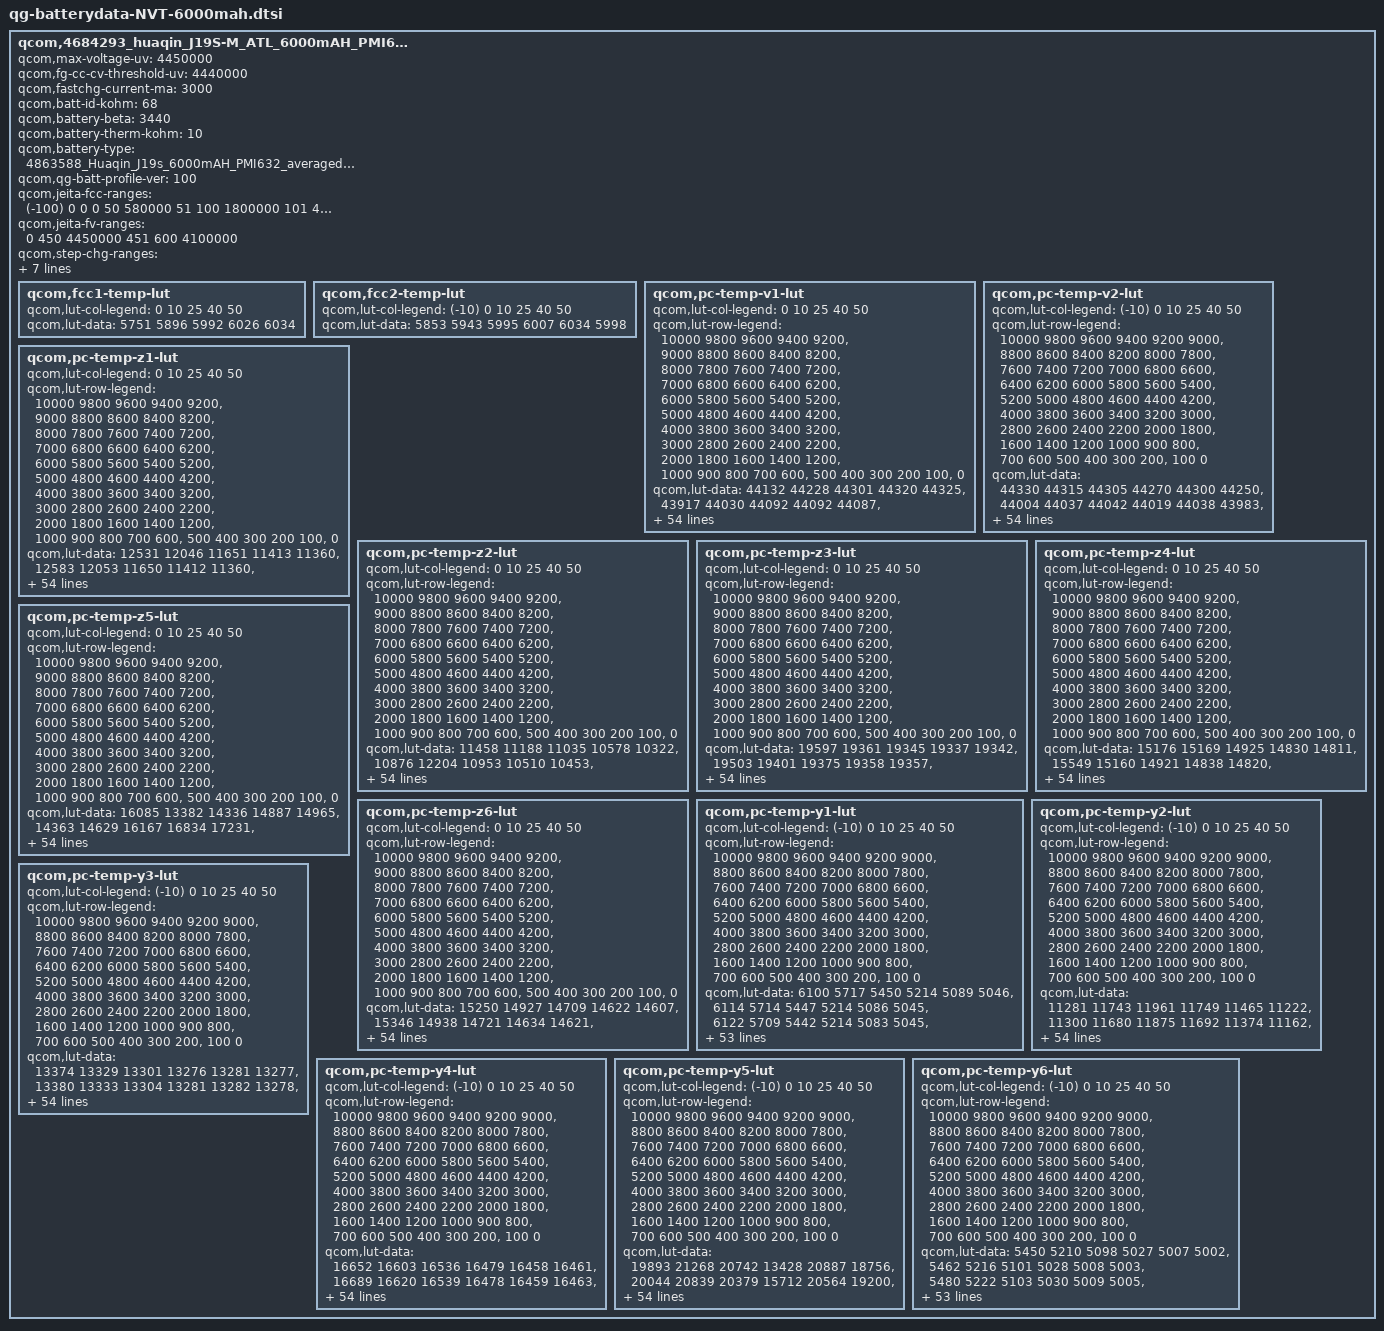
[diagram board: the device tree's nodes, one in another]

qcom,4684293_huaqin_J19S-M_ATL_6000mAH_PMI632 {
    /* 4684293_huaqin_J19S-M_ATL_6000mAH_PMI632_averaged_MasterSlave_Sep1th2020 */
    qcom,max-voltage-uv = <4450000>;
    qcom,fg-cc-cv-threshold-uv = <4440000>;
    qcom,fastchg-current-ma = <3000>;
    qcom,batt-id-kohm = <68>;
    qcom,battery-beta = <3440>;
    qcom,battery-therm-kohm = <10>;
    qcom,battery-type = "4863588_Huaqin_J19s_6000mAH_PMI632_averaged_MasterSlave_Oct22th2020";
    qcom,qg-batt-profile-ver = <100>;

	qcom,jeita-fcc-ranges = <(-100) 0 0
				0  50    580000
				51  100  1800000
				101 450  3000000
				451 600  3000000>;
	qcom,jeita-fv-ranges = <0   450   4450000
				451 600  4100000>;
	qcom,step-chg-ranges = <3600000  3800000  4500000
				3800001  4300000  3600000
				4300001  4350000  2500000>;
	qcom,ocv-based-step-chg;

	/* COOL = 5 DegC, WARM = 45 DegC */
	qcom,jeita-soft-thresholds = <0x439d 0x20b8>;
	/* COLD = 0 DegC, HOT = 60 DegC */
	qcom,jeita-hard-thresholds = <0x58cd 0x14f3>;
	/* COOL hys = 12 DegC, WARM hys = 40 DegC */
	qcom,jeita-soft-hys-thresholds = <0x4777 0x25e3>;
	qcom,jeita-soft-fcc-ua = <2500000 2500000>;
	qcom,jeita-soft-fv-uv = <4250000 4250000>;

	qcom,fcc1-temp-lut {
		qcom,lut-col-legend = <0 10 25 40 50>;
		qcom,lut-data = <5751 5896 5992 6026 6034>;
	};

	qcom,fcc2-temp-lut {
		qcom,lut-col-legend = <(-10) 0 10 25 40 50>;
		qcom,lut-data = <5853 5943 5995 6007 6034 5998>;
	};

	qcom,pc-temp-v1-lut {
		qcom,lut-col-legend = <0 10 25 40 50>;
		qcom,lut-row-legend = <10000 9800 9600 9400 9200>,
			<9000 8800 8600 8400 8200>,
			<8000 7800 7600 7400 7200>,
			<7000 6800 6600 6400 6200>,
			<6000 5800 5600 5400 5200>,
			<5000 4800 4600 4400 4200>,
			<4000 3800 3600 3400 3200>,
			<3000 2800 2600 2400 2200>,
			<2000 1800 1600 1400 1200>,
			<1000 900 800 700 600>,
			<500 400 300 200 100>,
			<0>;
		qcom,lut-data = <44132 44228 44301 44320 44325>,
			<43917 44030 44092 44092 44087>,
			<43700 43823 43881 43881 43874>,
			<43480 43606 43668 43670 43662>,
			<43255 43382 43455 43461 43451>,
			<43024 43153 43234 43247 43236>,
			<42792 42919 43001 43019 43010>,
			<42555 42682 42762 42781 42773>,
			<42319 42441 42524 42542 42535>,
			<42087 42201 42285 42301 42296>,
			<41858 41967 42048 42061 42058>,
			<41634 41736 41811 41824 41823>,
			<41416 41511 41576 41591 41589>,
			<41206 41291 41348 41362 41360>,
			<41001 41077 41126 41140 41137>,
			<40803 40873 40914 40924 40919>,
			<40611 40675 40712 40716 40710>,
			<40427 40486 40519 40515 40507>,
			<40249 40307 40339 40327 40318>,
			<40073 40131 40174 40159 40151>,
			<39908 39946 39991 39980 39976>,
			<39735 39753 39740 39738 39745>,
			<39517 39550 39470 39462 39475>,
			<39253 39309 39265 39254 39265>,
			<39043 39066 39102 39102 39112>,
			<38909 38913 38965 38970 38980>,
			<38804 38817 38854 38846 38852>,
			<38715 38735 38756 38733 38733>,
			<38640 38646 38659 38630 38626>,
			<38571 38560 38564 38537 38529>,
			<38505 38480 38478 38452 38442>,
			<38441 38405 38402 38371 38363>,
			<38384 38336 38333 38296 38290>,
			<38329 38275 38269 38228 38220>,
			<38279 38220 38211 38166 38153>,
			<38237 38170 38154 38105 38084>,
			<38203 38130 38100 38042 38015>,
			<38162 38087 38045 37977 37942>,
			<38104 38024 37973 37894 37853>,
			<38031 37937 37878 37785 37736>,
			<37942 37838 37772 37667 37610>,
			<37825 37721 37658 37554 37491>,
			<37688 37584 37527 37429 37364>,
			<37525 37417 37361 37262 37194>,
			<37365 37252 37209 37125 37060>,
			<37224 37137 37109 37040 36989>,
			<37179 37099 37075 37013 36962>,
			<37136 37075 37054 36989 36938>,
			<37100 37048 37028 36969 36912>,
			<37067 37004 36984 36902 36846>,
			<36994 36813 36761 36620 36573>,
			<36709 36362 36321 36166 36136>,
			<36203 35767 35742 35571 35560>,
			<35520 34933 34954 34754 34777>,
			<34375 33532 33743 33472 33556>,
			<30000 30000 30000 30000 30000>;
	};

	qcom,pc-temp-v2-lut {
		qcom,lut-col-legend = <(-10) 0 10 25 40 50>;
		qcom,lut-row-legend = <10000 9800 9600 9400 9200 9000>,
			<8800 8600 8400 8200 8000 7800>,
			<7600 7400 7200 7000 6800 6600>,
			<6400 6200 6000 5800 5600 5400>,
			<5200 5000 4800 4600 4400 4200>,
			<4000 3800 3600 3400 3200 3000>,
			<2800 2600 2400 2200 2000 1800>,
			<1600 1400 1200 1000 900 800>,
			<700 600 500 400 300 200>,
			<100 0>;
		qcom,lut-data = <44330 44315 44305 44270 44300 44250>,
			<44004 44037 44042 44019 44038 43983>,
			<43710 43775 43791 43780 43789 43731>,
			<43456 43534 43557 43553 43559 43498>,
			<43243 43314 43340 43340 43347 43285>,
			<43032 43093 43118 43122 43131 43069>,
			<42795 42854 42881 42888 42900 42837>,
			<42549 42609 42637 42646 42662 42599>,
			<42306 42365 42393 42406 42423 42362>,
			<42067 42122 42148 42166 42180 42121>,
			<41831 41882 41907 41928 41939 41883>,
			<41602 41645 41670 41691 41701 41646>,
			<41377 41413 41437 41456 41467 41414>,
			<41156 41189 41209 41227 41237 41186>,
			<40946 40974 40984 41002 41012 40963>,
			<40730 40764 40768 40785 40795 40749>,
			<40482 40563 40562 40577 40587 40543>,
			<40203 40364 40363 40376 40387 40345>,
			<39936 40145 40164 40186 40198 40160>,
			<39699 39892 39967 40008 40021 39987>,
			<39475 39639 39757 39811 39828 39801>,
			<39262 39407 39506 39548 39593 39564>,
			<39059 39187 39244 39269 39350 39310>,
			<38869 38993 39034 39058 39136 39101>,
			<38689 38820 38860 38888 38938 38920>,
			<38523 38664 38708 38742 38773 38765>,
			<38379 38526 38575 38614 38642 38634>,
			<38248 38402 38457 38501 38528 38521>,
			<38141 38284 38347 38396 38422 38416>,
			<38065 38169 38245 38299 38323 38317>,
			<38007 38066 38152 38210 38234 38228>,
			<37953 37985 38065 38127 38156 38151>,
			<37906 37916 37986 38051 38082 38078>,
			<37858 37860 37913 37979 38007 38001>,
			<37804 37819 37843 37913 37933 37921>,
			<37744 37781 37781 37841 37849 37832>,
			<37681 37739 37731 37752 37747 37720>,
			<37617 37697 37685 37657 37641 37599>,
			<37549 37645 37623 37566 37550 37497>,
			<37476 37580 37543 37477 37466 37411>,
			<37397 37497 37449 37380 37376 37322>,
			<37308 37378 37333 37271 37278 37222>,
			<37200 37213 37199 37149 37159 37109>,
			<37082 37043 37048 37005 37002 36962>,
			<36970 36883 36910 36898 36891 36849>,
			<36865 36767 36813 36859 36846 36804>,
			<36817 36732 36786 36839 36836 36791>,
			<36774 36692 36736 36821 36819 36774>,
			<36733 36652 36678 36770 36787 36744>,
			<36683 36598 36562 36601 36675 36648>,
			<36620 36490 36275 36157 36343 36303>,
			<36516 36169 35758 35565 35812 35797>,
			<36313 35571 35059 34761 35119 35131>,
			<35859 34672 34014 33536 34124 34192>,
			<34932 33339 32289 31776 32784 32738>,
			<33834 31683 28227 29230 27680 30138>;
	};

	qcom,pc-temp-z1-lut {
		qcom,lut-col-legend = <0 10 25 40 50>;
		qcom,lut-row-legend = <10000 9800 9600 9400 9200>,
			<9000 8800 8600 8400 8200>,
			<8000 7800 7600 7400 7200>,
			<7000 6800 6600 6400 6200>,
			<6000 5800 5600 5400 5200>,
			<5000 4800 4600 4400 4200>,
			<4000 3800 3600 3400 3200>,
			<3000 2800 2600 2400 2200>,
			<2000 1800 1600 1400 1200>,
			<1000 900 800 700 600>,
			<500 400 300 200 100>,
			<0>;
		qcom,lut-data = <12531 12046 11651 11413 11360>,
			<12583 12053 11650 11412 11360>,
			<12569 12053 11649 11410 11358>,
			<12553 12048 11647 11409 11357>,
			<12540 12039 11644 11407 11355>,
			<12526 12029 11640 11405 11354>,
			<12514 12018 11636 11404 11355>,
			<12500 12006 11631 11402 11355>,
			<12488 11993 11627 11402 11356>,
			<12478 11980 11622 11402 11359>,
			<12466 11970 11620 11402 11362>,
			<12458 11962 11620 11403 11365>,
			<12453 11956 11621 11405 11369>,
			<12444 11951 11620 11406 11370>,
			<12432 11948 11619 11405 11371>,
			<12415 11948 11619 11405 11371>,
			<12401 11950 11619 11404 11371>,
			<12394 11951 11619 11404 11371>,
			<12389 11951 11620 11404 11371>,
			<12386 11950 11622 11405 11372>,
			<12382 11950 11623 11405 11373>,
			<12379 11950 11624 11405 11373>,
			<12381 11950 11624 11404 11373>,
			<12387 11951 11625 11404 11374>,
			<12389 11952 11627 11404 11375>,
			<12391 11954 11629 11406 11377>,
			<12394 11960 11632 11408 11378>,
			<12395 11966 11635 11411 11380>,
			<12392 11967 11637 11413 11381>,
			<12390 11967 11639 11415 11383>,
			<12392 11969 11641 11417 11386>,
			<12396 11975 11644 11419 11388>,
			<12400 11982 11648 11420 11390>,
			<12409 11988 11652 11423 11392>,
			<12419 11994 11655 11426 11395>,
			<12424 11999 11660 11429 11397>,
			<12428 12006 11666 11432 11400>,
			<12435 12012 11673 11435 11402>,
			<12447 12015 11678 11438 11405>,
			<12462 12018 11682 11440 11407>,
			<12472 12021 11686 11443 11408>,
			<12482 12032 11691 11445 11411>,
			<12492 12042 11696 11447 11413>,
			<12514 12051 11702 11450 11415>,
			<12549 12062 11713 11454 11418>,
			<12527 12085 11721 11456 11419>,
			<12534 12072 11723 11456 11419>,
			<12535 12082 11723 11456 11420>,
			<12541 12091 11721 11458 11422>,
			<12534 12090 11732 11460 11425>,
			<12549 12102 11742 11465 11428>,
			<12562 12114 11753 11471 11435>,
			<12575 12129 11768 11480 11443>,
			<12590 12141 11781 11492 11456>,
			<12590 12141 11781 11492 11456>,
			<12590 12141 11781 11492 11456>;
	};

	qcom,pc-temp-z2-lut {
		qcom,lut-col-legend = <0 10 25 40 50>;
		qcom,lut-row-legend = <10000 9800 9600 9400 9200>,
			<9000 8800 8600 8400 8200>,
			<8000 7800 7600 7400 7200>,
			<7000 6800 6600 6400 6200>,
			<6000 5800 5600 5400 5200>,
			<5000 4800 4600 4400 4200>,
			<4000 3800 3600 3400 3200>,
			<3000 2800 2600 2400 2200>,
			<2000 1800 1600 1400 1200>,
			<1000 900 800 700 600>,
			<500 400 300 200 100>,
			<0>;
		qcom,lut-data = <11458 11188 11035 10578 10322>,
			<10876 12204 10953 10510 10453>,
			<10821 12374 10888 10578 10448>,
			<10796 11660 10845 10602 10448>,
			<10770 10976 10814 10574 10491>,
			<10747 10894 10787 10543 10541>,
			<10727 10856 10749 10533 10534>,
			<10707 10830 10707 10524 10495>,
			<10693 10811 10724 10512 10466>,
			<10691 10799 10952 10476 10444>,
			<10691 10798 11122 10447 10427>,
			<10694 10798 10964 10450 10424>,
			<10707 10798 10689 10459 10426>,
			<10728 10809 10630 10466 10428>,
			<10751 10831 10653 10478 10435>,
			<10776 10900 10689 10493 10445>,
			<10804 11102 10870 10516 10458>,
			<10839 11226 11161 10546 10483>,
			<10879 11139 11360 10557 10488>,
			<10918 11003 11725 10551 10413>,
			<10957 10982 11923 10546 10339>,
			<10992 10993 11627 10656 10454>,
			<11021 11000 11144 10883 10751>,
			<11048 11002 10954 10935 10844>,
			<11059 11003 10864 10799 10689>,
			<11046 11005 10828 10686 10544>,
			<11027 11013 10856 10753 10633>,
			<11023 11021 10897 10892 10855>,
			<11026 11027 10907 10916 10915>,
			<11031 11032 10901 10793 10743>,
			<11038 11034 10890 10666 10550>,
			<11049 11034 10866 10604 10461>,
			<11057 11034 10838 10559 10398>,
			<11064 11042 10832 10550 10349>,
			<11072 11061 10834 10553 10301>,
			<11080 11080 10839 10559 10275>,
			<11090 11098 10874 10595 10304>,
			<11104 11117 10937 10673 10387>,
			<11128 11146 10991 10756 10494>,
			<11157 11182 11047 10870 10676>,
			<11175 11199 11078 10937 10802>,
			<11184 11201 11086 10915 10809>,
			<11199 11204 11089 10884 10807>,
			<11235 11221 11068 10879 10835>,
			<11568 11402 11106 10886 10830>,
			<11545 11518 11122 10833 10648>,
			<11370 11511 11141 10737 10554>,
			<11282 11707 11100 10721 10585>,
			<11202 12151 11124 10808 10609>,
			<11119 12342 11183 10882 10694>,
			<11069 12198 11169 10757 10626>,
			<10955 11889 11064 10504 10324>,
			<10660 11647 10959 10410 10244>,
			<10499 11104 10884 10323 10174>,
			<10499 11104 10884 10323 10174>,
			<10499 11104 10884 10323 10174>;
	};

	qcom,pc-temp-z3-lut {
		qcom,lut-col-legend = <0 10 25 40 50>;
		qcom,lut-row-legend = <10000 9800 9600 9400 9200>,
			<9000 8800 8600 8400 8200>,
			<8000 7800 7600 7400 7200>,
			<7000 6800 6600 6400 6200>,
			<6000 5800 5600 5400 5200>,
			<5000 4800 4600 4400 4200>,
			<4000 3800 3600 3400 3200>,
			<3000 2800 2600 2400 2200>,
			<2000 1800 1600 1400 1200>,
			<1000 900 800 700 600>,
			<500 400 300 200 100>,
			<0>;
		qcom,lut-data = <19597 19361 19345 19337 19342>,
			<19503 19401 19375 19358 19357>,
			<19567 19422 19400 19378 19371>,
			<19613 19461 19417 19389 19382>,
			<19625 19497 19430 19394 19389>,
			<19633 19505 19438 19399 19396>,
			<19635 19510 19443 19403 19401>,
			<19635 19511 19446 19408 19405>,
			<19634 19511 19448 19409 19406>,
			<19633 19510 19456 19410 19406>,
			<19632 19508 19460 19411 19405>,
			<19630 19503 19453 19409 19403>,
			<19624 19498 19441 19405 19400>,
			<19615 19492 19433 19402 19397>,
			<19609 19487 19428 19398 19394>,
			<19604 19487 19425 19394 19391>,
			<19599 19495 19425 19392 19388>,
			<19592 19499 19428 19389 19384>,
			<19584 19486 19429 19385 19379>,
			<19580 19468 19430 19378 19371>,
			<19577 19467 19431 19372 19366>,
			<19575 19477 19431 19378 19368>,
			<19583 19486 19432 19391 19375>,
			<19608 19490 19429 19393 19376>,
			<19621 19492 19411 19376 19366>,
			<19614 19490 19399 19362 19356>,
			<19602 19478 19399 19377 19371>,
			<19593 19468 19399 19408 19407>,
			<19586 19469 19401 19416 19419>,
			<19580 19472 19413 19412 19414>,
			<19578 19475 19421 19408 19407>,
			<19577 19477 19420 19404 19400>,
			<19576 19478 19416 19398 19392>,
			<19574 19478 19413 19392 19384>,
			<19573 19476 19408 19382 19373>,
			<19571 19474 19404 19373 19364>,
			<19568 19470 19399 19366 19357>,
			<19565 19467 19395 19360 19352>,
			<19560 19463 19393 19360 19350>,
			<19553 19459 19392 19364 19351>,
			<19546 19454 19392 19367 19352>,
			<19537 19449 19387 19365 19355>,
			<19525 19442 19382 19364 19362>,
			<19507 19434 19379 19367 19367>,
			<19388 19411 19372 19363 19366>,
			<19346 19394 19362 19352 19353>,
			<19297 19391 19362 19340 19344>,
			<19291 19357 19356 19338 19330>,
			<19288 19293 19355 19327 19326>,
			<19286 19286 19343 19325 19320>,
			<19284 19290 19354 19343 19332>,
			<19289 19297 19364 19357 19350>,
			<19294 19296 19367 19357 19350>,
			<19306 19324 19370 19358 19352>,
			<19306 19324 19370 19358 19352>,
			<19306 19324 19370 19358 19352>;
	};

	qcom,pc-temp-z4-lut {
		qcom,lut-col-legend = <0 10 25 40 50>;
		qcom,lut-row-legend = <10000 9800 9600 9400 9200>,
			<9000 8800 8600 8400 8200>,
			<8000 7800 7600 7400 7200>,
			<7000 6800 6600 6400 6200>,
			<6000 5800 5600 5400 5200>,
			<5000 4800 4600 4400 4200>,
			<4000 3800 3600 3400 3200>,
			<3000 2800 2600 2400 2200>,
			<2000 1800 1600 1400 1200>,
			<1000 900 800 700 600>,
			<500 400 300 200 100>,
			<0>;
		qcom,lut-data = <15176 15169 14925 14830 14811>,
			<15549 15160 14921 14838 14820>,
			<15462 15140 14909 14830 14818>,
			<15358 15079 14890 14820 14814>,
			<15270 15007 14855 14804 14801>,
			<15184 14958 14821 14785 14782>,
			<15115 14917 14797 14769 14768>,
			<15061 14882 14776 14755 14755>,
			<15015 14853 14753 14741 14743>,
			<14975 14829 14721 14729 14731>,
			<14941 14810 14700 14717 14720>,
			<14913 14795 14698 14706 14710>,
			<14891 14782 14701 14697 14701>,
			<14873 14771 14699 14691 14695>,
			<14856 14761 14695 14688 14692>,
			<14841 14745 14690 14686 14690>,
			<14827 14721 14679 14683 14688>,
			<14816 14709 14666 14679 14687>,
			<14806 14719 14657 14676 14684>,
			<14795 14733 14643 14673 14679>,
			<14781 14736 14635 14670 14675>,
			<14770 14736 14667 14687 14691>,
			<14777 14736 14724 14728 14735>,
			<14806 14764 14760 14756 14761>,
			<14828 14811 14787 14776 14774>,
			<14838 14822 14799 14787 14781>,
			<14844 14817 14792 14766 14760>,
			<14844 14809 14776 14721 14709>,
			<14836 14798 14760 14701 14689>,
			<14825 14781 14739 14694 14686>,
			<14815 14768 14723 14690 14684>,
			<14805 14756 14715 14685 14681>,
			<14797 14748 14708 14682 14678>,
			<14791 14744 14705 14680 14675>,
			<14785 14741 14702 14679 14673>,
			<14781 14739 14700 14678 14672>,
			<14777 14738 14699 14677 14671>,
			<14772 14737 14699 14677 14670>,
			<14765 14735 14700 14678 14671>,
			<14755 14733 14703 14685 14684>,
			<14743 14730 14706 14690 14694>,
			<14727 14718 14703 14687 14687>,
			<14709 14703 14696 14683 14677>,
			<14687 14687 14690 14683 14681>,
			<14734 14661 14670 14671 14672>,
			<14763 14650 14655 14657 14654>,
			<14815 14646 14649 14660 14655>,
			<14817 14673 14641 14652 14655>,
			<14816 14740 14629 14644 14640>,
			<14815 14744 14631 14632 14631>,
			<14812 14742 14634 14652 14662>,
			<14812 14746 14638 14656 14670>,
			<14820 14753 14639 14660 14676>,
			<14826 14737 14640 14662 14677>,
			<14826 14737 14640 14662 14677>,
			<14826 14737 14640 14662 14677>;
	};

	qcom,pc-temp-z5-lut {
		qcom,lut-col-legend = <0 10 25 40 50>;
		qcom,lut-row-legend = <10000 9800 9600 9400 9200>,
			<9000 8800 8600 8400 8200>,
			<8000 7800 7600 7400 7200>,
			<7000 6800 6600 6400 6200>,
			<6000 5800 5600 5400 5200>,
			<5000 4800 4600 4400 4200>,
			<4000 3800 3600 3400 3200>,
			<3000 2800 2600 2400 2200>,
			<2000 1800 1600 1400 1200>,
			<1000 900 800 700 600>,
			<500 400 300 200 100>,
			<0>;
		qcom,lut-data = <16085 13382 14336 14887 14965>,
			<14363 14629 16167 16834 17231>,
			<15574 15379 17778 19023 19384>,
			<16599 16680 19126 20403 21219>,
			<17072 18009 20283 21084 22685>,
			<17417 18593 21314 21694 24031>,
			<17813 18997 22238 22598 25497>,
			<18271 19459 23068 23700 27016>,
			<18785 20082 24265 24772 28303>,
			<19430 20710 27382 25797 29283>,
			<20267 21184 29637 26824 30238>,
			<21038 21575 29042 27905 31496>,
			<21615 21990 27714 29001 33015>,
			<22160 22396 27795 29908 34339>,
			<22837 22907 28581 30579 35392>,
			<23707 24507 29636 31292 36398>,
			<24579 28593 32112 32560 37668>,
			<25266 30869 35756 34080 39050>,
			<25919 28912 38469 34377 39403>,
			<26911 26036 42030 33082 38040>,
			<28655 26471 45052 31959 36710>,
			<31451 31753 47979 35700 38048>,
			<38622 35530 50690 43708 41561>,
			<53252 35779 48426 44569 41948>,
			<60874 35897 34173 31280 30928>,
			<55148 35205 24032 20241 20656>,
			<45655 30177 22648 22806 24463>,
			<40774 26187 21899 28684 34385>,
			<37861 26454 22390 31136 38127>,
			<36404 27459 25657 31844 38565>,
			<36582 28815 28674 32410 38651>,
			<37235 31250 30135 33258 38005>,
			<38078 33866 31283 34121 36474>,
			<39526 35948 32357 34103 34759>,
			<41140 37810 33429 32472 32332>,
			<42182 38542 34110 30973 30690>,
			<42994 38679 34369 30465 30561>,
			<44008 38803 34578 30140 30508>,
			<46290 39262 34930 30645 30672>,
			<48875 40148 35671 34373 32157>,
			<49532 40530 36102 37060 33577>,
			<49390 40504 34001 33661 33892>,
			<48809 40459 31849 29690 34253>,
			<45570 40449 32631 32969 39691>,
			<26530 42287 35947 35064 42501>,
			<19522 36526 34159 29876 33097>,
			<13487 35644 35350 23126 24914>,
			<13205 20804 33269 24004 19965>,
			<13056 13671 37766 23009 22486>,
			<12916 13319 28315 26507 25152>,
			<12873 13556 33573 29441 26413>,
			<13075 13709 30640 25825 22503>,
			<12990 13496 29247 22851 19646>,
			<13504 15092 27619 20363 17642>,
			<13504 15092 27619 20363 17642>,
			<13504 15092 27619 20363 17642>;
	};

	qcom,pc-temp-z6-lut {
		qcom,lut-col-legend = <0 10 25 40 50>;
		qcom,lut-row-legend = <10000 9800 9600 9400 9200>,
			<9000 8800 8600 8400 8200>,
			<8000 7800 7600 7400 7200>,
			<7000 6800 6600 6400 6200>,
			<6000 5800 5600 5400 5200>,
			<5000 4800 4600 4400 4200>,
			<4000 3800 3600 3400 3200>,
			<3000 2800 2600 2400 2200>,
			<2000 1800 1600 1400 1200>,
			<1000 900 800 700 600>,
			<500 400 300 200 100>,
			<0>;
		qcom,lut-data = <15250 14927 14709 14622 14607>,
			<15346 14938 14721 14634 14621>,
			<15325 14939 14727 14641 14627>,
			<15296 14926 14726 14643 14629>,
			<15261 14908 14717 14639 14627>,
			<15217 14892 14707 14633 14624>,
			<15180 14872 14699 14629 14622>,
			<15149 14853 14690 14625 14619>,
			<15122 14837 14682 14621 14615>,
			<15098 14823 14673 14616 14611>,
			<15078 14811 14665 14612 14607>,
			<15059 14799 14659 14606 14602>,
			<15041 14789 14654 14600 14597>,
			<15024 14779 14649 14596 14593>,
			<15009 14771 14645 14592 14590>,
			<14996 14764 14640 14589 14587>,
			<14985 14759 14637 14586 14584>,
			<14973 14754 14633 14583 14581>,
			<14963 14751 14629 14579 14577>,
			<14954 14748 14624 14573 14570>,
			<14947 14748 14622 14569 14565>,
			<14942 14752 14637 14581 14574>,
			<14949 14759 14662 14607 14597>,
			<14976 14775 14671 14615 14606>,
			<14991 14796 14674 14615 14606>,
			<14991 14800 14675 14615 14606>,
			<14989 14793 14672 14614 14605>,
			<14986 14785 14666 14611 14603>,
			<14980 14780 14662 14608 14601>,
			<14973 14776 14659 14604 14598>,
			<14969 14772 14657 14599 14594>,
			<14965 14769 14653 14595 14589>,
			<14962 14767 14649 14591 14584>,
			<14959 14766 14646 14587 14578>,
			<14957 14765 14643 14582 14573>,
			<14956 14764 14640 14577 14567>,
			<14956 14763 14638 14573 14563>,
			<14955 14762 14636 14570 14559>,
			<14954 14762 14637 14570 14559>,
			<14952 14761 14639 14575 14564>,
			<14949 14759 14640 14579 14569>,
			<14944 14755 14638 14577 14568>,
			<14939 14749 14633 14575 14567>,
			<14931 14741 14630 14576 14571>,
			<14903 14725 14620 14570 14568>,
			<14897 14714 14610 14558 14553>,
			<14895 14711 14607 14553 14549>,
			<14894 14707 14602 14549 14543>,
			<14895 14706 14596 14539 14534>,
			<14896 14707 14592 14534 14526>,
			<14899 14713 14602 14552 14546>,
			<14909 14723 14611 14564 14562>,
			<14922 14732 14616 14568 14568>,
			<14944 14748 14623 14572 14573>,
			<14944 14748 14623 14572 14573>,
			<14944 14748 14623 14572 14573>;
	};

	qcom,pc-temp-y1-lut {
		qcom,lut-col-legend = <(-10) 0 10 25 40 50>;
		qcom,lut-row-legend = <10000 9800 9600 9400 9200 9000>,
			<8800 8600 8400 8200 8000 7800>,
			<7600 7400 7200 7000 6800 6600>,
			<6400 6200 6000 5800 5600 5400>,
			<5200 5000 4800 4600 4400 4200>,
			<4000 3800 3600 3400 3200 3000>,
			<2800 2600 2400 2200 2000 1800>,
			<1600 1400 1200 1000 900 800>,
			<700 600 500 400 300 200>,
			<100 0>;
		qcom,lut-data = <6100 5717 5450 5214 5089 5046>,
			<6114 5714 5447 5214 5086 5045>,
			<6122 5709 5442 5214 5083 5045>,
			<6126 5702 5437 5213 5080 5044>,
			<6126 5697 5432 5213 5077 5043>,
			<6124 5694 5430 5212 5075 5043>,
			<6117 5694 5428 5209 5072 5043>,
			<6107 5694 5427 5207 5070 5043>,
			<6101 5693 5426 5206 5069 5042>,
			<6103 5688 5424 5205 5068 5042>,
			<6107 5684 5422 5205 5067 5042>,
			<6110 5687 5419 5204 5067 5042>,
			<6115 5693 5415 5203 5066 5043>,
			<6117 5694 5413 5203 5066 5043>,
			<6112 5694 5411 5203 5065 5043>,
			<6105 5693 5410 5203 5065 5043>,
			<6109 5692 5412 5203 5065 5043>,
			<6122 5690 5416 5203 5066 5044>,
			<6127 5690 5416 5203 5066 5044>,
			<6119 5692 5415 5205 5065 5045>,
			<6109 5694 5413 5207 5065 5045>,
			<6107 5693 5413 5207 5065 5045>,
			<6116 5691 5413 5206 5067 5045>,
			<6125 5691 5414 5207 5068 5046>,
			<6133 5699 5418 5209 5069 5046>,
			<6143 5707 5422 5211 5070 5046>,
			<6144 5708 5424 5212 5071 5047>,
			<6131 5706 5426 5212 5072 5048>,
			<6118 5705 5428 5213 5073 5049>,
			<6115 5707 5432 5216 5075 5051>,
			<6113 5710 5435 5219 5077 5053>,
			<6110 5710 5435 5222 5078 5053>,
			<6099 5709 5435 5225 5079 5054>,
			<6087 5708 5435 5226 5080 5055>,
			<6084 5709 5438 5226 5082 5056>,
			<6087 5710 5440 5227 5083 5057>,
			<6090 5708 5443 5228 5084 5058>,
			<6094 5705 5447 5231 5085 5058>,
			<6102 5706 5449 5233 5085 5059>,
			<6110 5716 5451 5235 5086 5061>,
			<6117 5726 5452 5236 5086 5062>,
			<6120 5726 5454 5237 5088 5063>,
			<6108 5722 5458 5238 5089 5063>,
			<6097 5719 5464 5240 5090 5063>,
			<6103 5717 5472 5246 5093 5065>,
			<6116 5726 5475 5250 5093 5066>,
			<6133 5738 5485 5250 5094 5066>,
			<6128 5733 5487 5250 5093 5067>,
			<6136 5737 5492 5246 5093 5066>,
			<6173 5752 5496 5249 5094 5067>,
			<6191 5767 5505 5257 5096 5069>,
			<6254 5805 5506 5265 5100 5072>,
			<6307 5855 5554 5275 5106 5079>,
			<6288 5927 5615 5302 5115 5085>,
			<6288 5927 5615 5302 5115 5085>,
			<6288 5927 5615 5302 5115 5085>;
	};

	qcom,pc-temp-y2-lut {
		qcom,lut-col-legend = <(-10) 0 10 25 40 50>;
		qcom,lut-row-legend = <10000 9800 9600 9400 9200 9000>,
			<8800 8600 8400 8200 8000 7800>,
			<7600 7400 7200 7000 6800 6600>,
			<6400 6200 6000 5800 5600 5400>,
			<5200 5000 4800 4600 4400 4200>,
			<4000 3800 3600 3400 3200 3000>,
			<2800 2600 2400 2200 2000 1800>,
			<1600 1400 1200 1000 900 800>,
			<700 600 500 400 300 200>,
			<100 0>;
		qcom,lut-data = <11281 11743 11961 11749 11465 11222>,
			<11300 11680 11875 11692 11374 11162>,
			<11309 11619 11794 11625 11287 11090>,
			<11309 11562 11718 11555 11206 11018>,
			<11304 11510 11651 11490 11135 10958>,
			<11296 11462 11593 11439 11076 10919>,
			<11275 11416 11545 11394 11022 10895>,
			<11247 11376 11504 11353 10980 10878>,
			<11239 11355 11465 11324 10970 10877>,
			<11246 11341 11423 11297 10977 10888>,
			<11259 11335 11404 11284 10981 10895>,
			<11283 11350 11407 11288 10965 10870>,
			<11322 11387 11414 11295 10943 10831>,
			<11358 11424 11428 11297 10943 10821>,
			<11392 11462 11459 11298 10956 10834>,
			<11417 11505 11500 11299 10971 10840>,
			<11419 11568 11549 11317 10991 10822>,
			<11418 11638 11607 11354 11021 10798>,
			<11417 11656 11670 11415 11059 10807>,
			<11415 11648 11746 11529 11112 10891>,
			<11412 11640 11786 11596 11174 10980>,
			<11411 11634 11770 11594 11269 11044>,
			<11411 11627 11744 11588 11353 11100>,
			<11412 11629 11744 11598 11363 11135>,
			<11414 11642 11771 11637 11356 11168>,
			<11419 11658 11798 11672 11352 11187>,
			<11430 11672 11817 11691 11357 11197>,
			<11462 11689 11833 11706 11369 11212>,
			<11489 11710 11841 11718 11401 11242>,
			<11490 11740 11844 11737 11469 11328>,
			<11479 11772 11844 11758 11526 11416>,
			<11443 11804 11850 11794 11566 11481>,
			<11053 11846 11861 11832 11591 11540>,
			<10575 11861 11870 11834 11622 11599>,
			<10285 11793 11884 11809 11712 11666>,
			<9882 11676 11891 11788 11742 11699>,
			<9705 11558 11862 11755 11686 11645>,
			<9689 11416 11801 11722 11621 11555>,
			<9681 11268 11745 11721 11589 11523>,
			<9675 11138 11689 11729 11565 11516>,
			<9672 10978 11617 11727 11559 11510>,
			<9669 10615 11492 11707 11578 11455>,
			<9667 10008 11335 11682 11578 11375>,
			<9664 9785 11197 11659 11457 11276>,
			<9662 9706 10993 11597 11322 11127>,
			<9659 9677 10867 11517 11193 11013>,
			<9657 9671 10753 11473 11178 11004>,
			<9656 9665 10398 11497 11193 11020>,
			<9654 9661 10052 11487 11234 11085>,
			<9651 9656 9837 11504 11226 11090>,
			<9650 9653 9692 11406 11121 10942>,
			<9649 9650 9662 11316 11005 10881>,
			<9648 9649 9654 11168 10892 10729>,
			<9648 9649 9654 11029 10655 10568>,
			<9648 9649 9654 11029 10655 10568>,
			<9648 9649 9654 11029 10655 10568>;
	};

	qcom,pc-temp-y3-lut {
		qcom,lut-col-legend = <(-10) 0 10 25 40 50>;
		qcom,lut-row-legend = <10000 9800 9600 9400 9200 9000>,
			<8800 8600 8400 8200 8000 7800>,
			<7600 7400 7200 7000 6800 6600>,
			<6400 6200 6000 5800 5600 5400>,
			<5200 5000 4800 4600 4400 4200>,
			<4000 3800 3600 3400 3200 3000>,
			<2800 2600 2400 2200 2000 1800>,
			<1600 1400 1200 1000 900 800>,
			<700 600 500 400 300 200>,
			<100 0>;
		qcom,lut-data = <13374 13329 13301 13276 13281 13277>,
			<13380 13333 13304 13281 13282 13278>,
			<13389 13337 13307 13285 13282 13279>,
			<13399 13341 13309 13288 13283 13280>,
			<13407 13344 13311 13289 13283 13281>,
			<13412 13346 13312 13290 13284 13281>,
			<13413 13348 13312 13289 13284 13282>,
			<13413 13350 13312 13287 13284 13282>,
			<13414 13352 13312 13287 13284 13283>,
			<13413 13354 13313 13292 13286 13283>,
			<13413 13355 13314 13296 13286 13284>,
			<13413 13354 13315 13296 13287 13284>,
			<13414 13352 13317 13297 13287 13285>,
			<13414 13350 13317 13297 13287 13285>,
			<13411 13349 13317 13296 13287 13285>,
			<13404 13349 13316 13296 13287 13285>,
			<13399 13349 13316 13296 13289 13286>,
			<13393 13351 13317 13298 13292 13288>,
			<13388 13351 13317 13299 13293 13289>,
			<13383 13346 13319 13300 13294 13291>,
			<13378 13339 13320 13301 13294 13292>,
			<13374 13335 13316 13298 13292 13289>,
			<13371 13331 13310 13292 13288 13284>,
			<13368 13328 13306 13290 13286 13282>,
			<13363 13326 13303 13288 13283 13280>,
			<13357 13324 13302 13287 13281 13280>,
			<13349 13323 13301 13286 13281 13280>,
			<13333 13323 13301 13285 13280 13280>,
			<13322 13322 13301 13285 13279 13280>,
			<13319 13317 13300 13285 13278 13279>,
			<13317 13312 13300 13285 13278 13278>,
			<13318 13309 13300 13285 13278 13278>,
			<13324 13306 13299 13285 13278 13279>,
			<13335 13305 13299 13286 13279 13280>,
			<13350 13308 13297 13286 13280 13281>,
			<13373 13313 13296 13286 13280 13281>,
			<13400 13318 13297 13285 13279 13280>,
			<13433 13324 13299 13285 13278 13279>,
			<13472 13330 13300 13285 13279 13279>,
			<13519 13339 13301 13285 13280 13280>,
			<13577 13346 13302 13286 13281 13281>,
			<13647 13349 13304 13286 13282 13280>,
			<13731 13350 13306 13286 13282 13280>,
			<13842 13364 13310 13284 13279 13278>,
			<14012 13409 13316 13284 13280 13278>,
			<14273 13487 13316 13290 13284 13283>,
			<14457 13539 13323 13291 13287 13285>,
			<14662 13656 13327 13295 13289 13288>,
			<15044 13882 13344 13296 13290 13289>,
			<15993 14303 13382 13296 13288 13287>,
			<18027 15250 13482 13292 13284 13283>,
			<22373 17989 13795 13296 13285 13283>,
			<33012 26447 15207 13304 13288 13287>,
			<65535 65085 20503 13323 13295 13295>,
			<65535 65085 20503 13323 13295 13295>,
			<65535 65085 20503 13323 13295 13295>;
	};

	qcom,pc-temp-y4-lut {
		qcom,lut-col-legend = <(-10) 0 10 25 40 50>;
		qcom,lut-row-legend = <10000 9800 9600 9400 9200 9000>,
			<8800 8600 8400 8200 8000 7800>,
			<7600 7400 7200 7000 6800 6600>,
			<6400 6200 6000 5800 5600 5400>,
			<5200 5000 4800 4600 4400 4200>,
			<4000 3800 3600 3400 3200 3000>,
			<2800 2600 2400 2200 2000 1800>,
			<1600 1400 1200 1000 900 800>,
			<700 600 500 400 300 200>,
			<100 0>;
		qcom,lut-data = <16652 16603 16536 16479 16458 16461>,
			<16689 16620 16539 16478 16459 16463>,
			<16763 16641 16542 16477 16461 16465>,
			<16850 16664 16546 16477 16462 16466>,
			<16924 16681 16549 16478 16463 16468>,
			<16962 16689 16550 16479 16465 16468>,
			<16965 16686 16551 16483 16465 16468>,
			<16966 16682 16552 16488 16466 16467>,
			<16969 16682 16553 16488 16467 16467>,
			<16975 16683 16555 16484 16466 16466>,
			<16983 16685 16558 16482 16466 16467>,
			<16988 16694 16562 16484 16468 16467>,
			<16993 16711 16568 16489 16471 16469>,
			<17000 16731 16577 16494 16474 16471>,
			<17014 16756 16592 16503 16477 16473>,
			<17027 16779 16610 16513 16481 16476>,
			<17011 16794 16636 16524 16484 16479>,
			<16940 16806 16663 16536 16488 16483>,
			<16872 16806 16673 16556 16498 16491>,
			<16830 16766 16678 16591 16518 16508>,
			<16794 16715 16680 16609 16528 16518>,
			<16755 16675 16641 16573 16522 16509>,
			<16714 16636 16574 16514 16510 16493>,
			<16677 16607 16542 16491 16494 16481>,
			<16642 16586 16524 16479 16472 16469>,
			<16613 16568 16515 16474 16463 16463>,
			<16606 16555 16511 16476 16463 16463>,
			<16610 16543 16508 16479 16465 16463>,
			<16615 16534 16507 16483 16468 16465>,
			<16621 16525 16506 16487 16474 16470>,
			<16626 16519 16504 16492 16480 16476>,
			<16630 16517 16502 16497 16488 16483>,
			<16641 16517 16499 16502 16496 16491>,
			<16654 16517 16495 16507 16501 16497>,
			<16668 16521 16489 16512 16504 16503>,
			<16693 16528 16486 16513 16505 16505>,
			<16710 16541 16490 16500 16495 16496>,
			<16720 16565 16497 16480 16484 16482>,
			<16727 16586 16503 16473 16485 16480>,
			<16728 16602 16509 16470 16488 16488>,
			<16726 16614 16516 16469 16492 16496>,
			<16723 16617 16526 16473 16497 16504>,
			<16716 16618 16536 16476 16497 16509>,
			<16711 16617 16542 16463 16466 16477>,
			<16716 16613 16545 16462 16449 16460>,
			<16729 16618 16535 16472 16467 16484>,
			<16736 16620 16548 16493 16501 16519>,
			<16725 16636 16572 16528 16537 16555>,
			<16729 16651 16608 16556 16573 16586>,
			<16830 16681 16656 16548 16563 16590>,
			<17077 16743 16706 16488 16497 16496>,
			<17618 17092 16762 16499 16478 16485>,
			<18969 19110 17019 16522 16477 16481>,
			<24782 39481 20993 16625 16484 16475>,
			<24782 39481 20993 16625 16484 16475>,
			<24782 39481 20993 16625 16484 16475>;
	};

	qcom,pc-temp-y5-lut {
		qcom,lut-col-legend = <(-10) 0 10 25 40 50>;
		qcom,lut-row-legend = <10000 9800 9600 9400 9200 9000>,
			<8800 8600 8400 8200 8000 7800>,
			<7600 7400 7200 7000 6800 6600>,
			<6400 6200 6000 5800 5600 5400>,
			<5200 5000 4800 4600 4400 4200>,
			<4000 3800 3600 3400 3200 3000>,
			<2800 2600 2400 2200 2000 1800>,
			<1600 1400 1200 1000 900 800>,
			<700 600 500 400 300 200>,
			<100 0>;
		qcom,lut-data = <19893 21268 20742 13428 20887 18756>,
			<20044 20839 20379 15712 20564 19200>,
			<20105 20426 19948 17037 20222 19466>,
			<20095 20035 19516 17640 19861 19593>,
			<20033 19674 19148 17759 19484 19621>,
			<19939 19353 18912 17631 19090 19589>,
			<19765 19076 18347 16624 18626 19436>,
			<19509 18821 17506 15218 18186 19194>,
			<19315 18562 17089 15254 17974 19040>,
			<19142 18299 16719 16788 17980 19005>,
			<19031 18002 16417 17763 18019 18913>,
			<19183 17460 16235 17525 17730 18493>,
			<19698 16812 16115 17023 17241 17863>,
			<20264 16662 15960 16450 16848 17322>,
			<20941 16827 15440 15590 16280 16710>,
			<21641 17138 15106 15071 16009 16399>,
			<22146 18342 15311 14991 16389 16570>,
			<22559 20550 15846 14987 16890 16838>,
			<22913 21856 16986 15218 16837 16857>,
			<23262 22519 19996 16202 16380 16683>,
			<23547 23013 22182 17443 16178 16569>,
			<23666 23453 22697 19234 18238 17475>,
			<23738 23828 23001 20944 20789 19030>,
			<23759 24029 23096 21138 21013 19744>,
			<23052 24081 22844 20774 20677 20151>,
			<21352 24141 22654 20375 20227 20321>,
			<19408 24453 22960 19971 19490 19999>,
			<16386 25010 23479 19633 18587 19297>,
			<14114 25112 23724 19620 17713 18456>,
			<13682 22920 23884 19811 16799 17225>,
			<13457 20085 24097 20077 16473 16558>,
			<13403 18617 24807 20572 16682 16754>,
			<13686 17505 25724 21347 17072 17237>,
			<13968 17180 25620 22287 17875 18106>,
			<13927 17835 23981 23527 19404 20016>,
			<13811 18877 22868 24591 20176 21143>,
			<13834 19760 23349 25601 20299 21058>,
			<13981 20694 24133 26440 20420 20924>,
			<14130 21609 24135 26543 21412 21051>,
			<14235 22794 23157 26387 23694 21853>,
			<14391 23735 22107 26122 24548 22375>,
			<14470 22013 21018 25159 24087 21799>,
			<14042 16368 20247 23753 23649 21215>,
			<13363 14737 20927 22282 23379 21816>,
			<12895 14364 21273 20725 23865 21784>,
			<12606 13935 19841 22182 20844 18830>,
			<12536 13848 20219 20296 19098 16686>,
			<12810 13611 17320 20544 17429 15795>,
			<13031 13879 16291 19624 16757 15484>,
			<12128 13851 15629 19887 15967 14899>,
			<11163 13342 14954 21384 16518 15994>,
			<10301 11196 14219 22094 16960 15289>,
			<9834 9613 12812 23515 16866 15460>,
			<9443 8922 9627 23894 22328 17130>,
			<9443 8922 9627 23894 22328 17130>,
			<9443 8922 9627 23894 22328 17130>;
	};

	qcom,pc-temp-y6-lut {
		qcom,lut-col-legend = <(-10) 0 10 25 40 50>;
		qcom,lut-row-legend = <10000 9800 9600 9400 9200 9000>,
			<8800 8600 8400 8200 8000 7800>,
			<7600 7400 7200 7000 6800 6600>,
			<6400 6200 6000 5800 5600 5400>,
			<5200 5000 4800 4600 4400 4200>,
			<4000 3800 3600 3400 3200 3000>,
			<2800 2600 2400 2200 2000 1800>,
			<1600 1400 1200 1000 900 800>,
			<700 600 500 400 300 200>,
			<100 0>;
		qcom,lut-data = <5450 5210 5098 5027 5007 5002>,
			<5462 5216 5101 5028 5008 5003>,
			<5480 5222 5103 5030 5009 5005>,
			<5499 5228 5104 5031 5009 5006>,
			<5516 5233 5105 5033 5010 5007>,
			<5523 5235 5105 5033 5011 5008>,
			<5522 5234 5105 5033 5011 5008>,
			<5520 5232 5104 5033 5011 5008>,
			<5518 5231 5104 5034 5012 5008>,
			<5517 5231 5104 5036 5012 5009>,
			<5516 5232 5105 5038 5013 5010>,
			<5517 5233 5106 5039 5014 5010>,
			<5517 5235 5108 5040 5014 5011>,
			<5518 5238 5111 5042 5015 5011>,
			<5519 5244 5115 5044 5016 5012>,
			<5520 5250 5119 5046 5018 5013>,
			<5514 5255 5126 5050 5020 5015>,
			<5490 5259 5133 5055 5023 5017>,
			<5467 5259 5137 5061 5027 5021>,
			<5454 5244 5139 5072 5033 5026>,
			<5442 5226 5140 5077 5036 5030>,
			<5430 5212 5127 5064 5032 5025>,
			<5419 5198 5103 5044 5026 5017>,
			<5410 5189 5092 5035 5019 5011>,
			<5401 5182 5085 5030 5011 5006>,
			<5393 5177 5082 5029 5007 5004>,
			<5390 5175 5081 5029 5007 5004>,
			<5389 5173 5081 5029 5007 5005>,
			<5388 5170 5081 5030 5007 5005>,
			<5391 5167 5081 5032 5008 5006>,
			<5401 5165 5081 5033 5010 5007>,
			<5414 5165 5081 5035 5012 5009>,
			<5431 5165 5081 5037 5015 5012>,
			<5455 5167 5080 5039 5017 5015>,
			<5486 5173 5079 5041 5019 5017>,
			<5528 5183 5078 5041 5019 5018>,
			<5574 5197 5081 5037 5016 5015>,
			<5623 5219 5086 5032 5012 5010>,
			<5675 5245 5091 5030 5012 5009>,
			<5730 5275 5095 5030 5015 5013>,
			<5785 5308 5102 5030 5017 5016>,
			<5849 5335 5110 5032 5019 5018>,
			<5924 5360 5121 5033 5019 5019>,
			<6022 5402 5135 5029 5007 5008>,
			<6173 5473 5154 5029 5005 5004>,
			<6404 5586 5157 5037 5013 5015>,
			<6568 5654 5178 5044 5025 5027>,
			<6744 5778 5209 5057 5037 5039>,
			<7068 5987 5271 5066 5048 5049>,
			<7859 6356 5371 5063 5044 5048>,
			<9430 7137 5539 5044 5022 5019>,
			<12630 9263 5902 5053 5018 5017>,
			<20237 15665 7113 5068 5021 5020>,
			<43788 45401 12101 5118 5030 5025>,
			<43788 45401 12101 5118 5030 5025>,
			<43788 45401 12101 5118 5030 5025>;
	};

};
